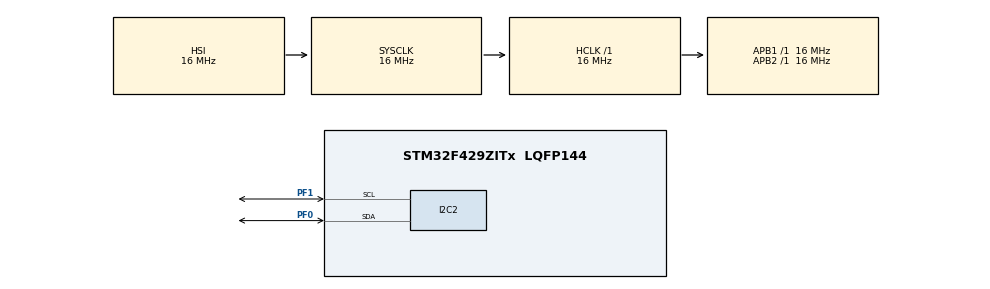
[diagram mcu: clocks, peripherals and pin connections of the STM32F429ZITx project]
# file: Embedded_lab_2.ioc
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I2C2.I2C_Coeff_DF=5
I2C2.I2C_Mode=I2C_Fast
I2C2.NoStretchMode=I2C_NOSTRETCH_ENABLE
I2C2.OwnAddress=4
Mcu.Family=STM32F4
Mcu.Name=STM32F429ZITx
Mcu.Package=LQFP144
NVIC.I2C2_ER_IRQn=true\:0\:0\:false\:false\:true\:true\:true\:true
NVIC.I2C2_EV_IRQn=true\:0\:0\:false\:false\:true\:true\:true\:true
NVIC.PriorityGroup=NVIC_PRIORITYGROUP_4
PA13.Mode=Serial_Wire
PA13.Signal=SYS_JTMS-SWDIO
PA14.Mode=Serial_Wire
PA14.Signal=SYS_JTCK-SWCLK
PF0.GPIO_Pu=GPIO_PULLUP
PF0.Mode=I2C
PF0.Signal=I2C2_SDA
PF1.GPIO_Pu=GPIO_PULLUP
PF1.Mode=I2C
PF1.Signal=I2C2_SCL
PH0/OSC_IN.Mode=HSE-External-Oscillator
PH0/OSC_IN.Signal=RCC_OSC_IN
PH1/OSC_OUT.Mode=HSE-External-Oscillator
PH1/OSC_OUT.Signal=RCC_OSC_OUT
ProjectManager.HeapSize=0x200
ProjectManager.StackSize=0x400
ProjectManager.TargetToolchain=STM32CubeIDE
RCC.AHBFreq_Value=16000000
RCC.APB1Freq_Value=16000000
RCC.APB2Freq_Value=16000000
RCC.CortexFreq_Value=16000000
RCC.HSE_VALUE=25000000
RCC.HSI_VALUE=16000000
RCC.LSE_VALUE=32768
RCC.SYSCLKFreq_VALUE=16000000
RCC.VCOOutputFreq_Value=192000000
board=custom

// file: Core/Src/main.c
/* USER CODE BEGIN Header */
/**
  ******************************************************************************
  * @file           : main.c
  * @brief          : Main program body
  ******************************************************************************
  * @attention
  *
  * Copyright (c) 2023 STMicroelectronics.
  * All rights reserved.
  *
  * This software is licensed under terms that can be found in the LICENSE file
  * in the root directory of this software component.
  * If no LICENSE file comes with this software, it is provided AS-IS.
  *
  ******************************************************************************
  */
/* USER CODE END Header */
#include "main.h"
#include "i2c.h"
#include "gpio.h"

/* USER CODE BEGIN PV */
volatile uint8_t tx_speed [2];
volatile uint8_t rx_signal [5];
volatile uint8_t rx_pos [9];

volatile int8_t signal_left = 20;
volatile int8_t signal_right = 20;

volatile int16_t v_left = 0;
volatile int16_t v_right = 0;

volatile int32_t pos_left = 0;
volatile int32_t pos_right = 0;
/* USER CODE END PV */

void SystemClock_Config(void);

int main(void)
{

  /* MCU Configuration--------------------------------------------------------*/

  /* Reset of all peripherals, Initializes the Flash interface and the Systick. */
  HAL_Init();

  /* Configure the system clock */
  SystemClock_Config();

  /* Initialize all configured peripherals */
  MX_GPIO_Init();
  MX_I2C2_Init();
  /* USER CODE BEGIN 2 */
  HAL_I2C_Init(&hi2c2);
  /* USER CODE END 2 */

  /* Infinite loop */
  /* USER CODE BEGIN WHILE */
  while (1)
  {
	  // receive 4 angle bytes for each wheel with I2C then convert them to int32_t
	  HAL_I2C_Slave_Receive(&hi2c2 ,(uint8_t *)rx_pos, 9,100);
	  pos_left = (int32_t) (rx_pos[1]<<24) + (rx_pos[2]<<16) + (rx_pos[3]<<8) + rx_pos[4];
	  pos_right = (int32_t) (rx_pos[5]<<24) + (rx_pos[6]<<16) + (rx_pos[7]<<8) + rx_pos[8];

	  // use this for reading speed
//	  HAL_I2C_Slave_Receive(&hi2c2 ,(uint8_t *)rx_signal, 5,100);
//	  v_left = (int16_t) (rx_signal[1]<<8) +  rx_signal[2];
//	  v_right = (int16_t) (rx_signal[3]<<8) + rx_signal[4];

	  // set control signal (-100 to 100)
	  tx_speed[0] = signal_left;
	  tx_speed[1] = signal_right;
	  HAL_I2C_Slave_Transmit(&hi2c2 ,(uint8_t *)tx_speed, 2,100);

    /* USER CODE END WHILE */

  }
}

void SystemClock_Config(void)
{
  RCC_OscInitTypeDef RCC_OscInitStruct = {0};
  RCC_ClkInitTypeDef RCC_ClkInitStruct = {0};

  /** Configure the main internal regulator output voltage
  */
  __HAL_RCC_PWR_CLK_ENABLE();
  __HAL_PWR_VOLTAGESCALING_CONFIG(PWR_REGULATOR_VOLTAGE_SCALE3);

  /** Initializes the RCC Oscillators according to the specified parameters
  * in the RCC_OscInitTypeDef structure.
  */
  RCC_OscInitStruct.OscillatorType = RCC_OSCILLATORTYPE_HSI;
  RCC_OscInitStruct.HSIState = RCC_HSI_ON;
  RCC_OscInitStruct.HSICalibrationValue = RCC_HSICALIBRATION_DEFAULT;
  RCC_OscInitStruct.PLL.PLLState = RCC_PLL_NONE;
  if (HAL_RCC_OscConfig(&RCC_OscInitStruct) != HAL_OK)
  {
    Error_Handler();
  }

  /** Initializes the CPU, AHB and APB buses clocks
  */
  RCC_ClkInitStruct.ClockType = RCC_CLOCKTYPE_HCLK|RCC_CLOCKTYPE_SYSCLK
                              |RCC_CLOCKTYPE_PCLK1|RCC_CLOCKTYPE_PCLK2;
  RCC_ClkInitStruct.SYSCLKSource = RCC_SYSCLKSOURCE_HSI;
  RCC_ClkInitStruct.AHBCLKDivider = RCC_SYSCLK_DIV1;
  RCC_ClkInitStruct.APB1CLKDivider = RCC_HCLK_DIV1;
  RCC_ClkInitStruct.APB2CLKDivider = RCC_HCLK_DIV1;

  if (HAL_RCC_ClockConfig(&RCC_ClkInitStruct, FLASH_LATENCY_0) != HAL_OK)
  {
    Error_Handler();
  }
}

void Error_Handler(void)
{
  __disable_irq();
  while (1)
  {
  }
}
